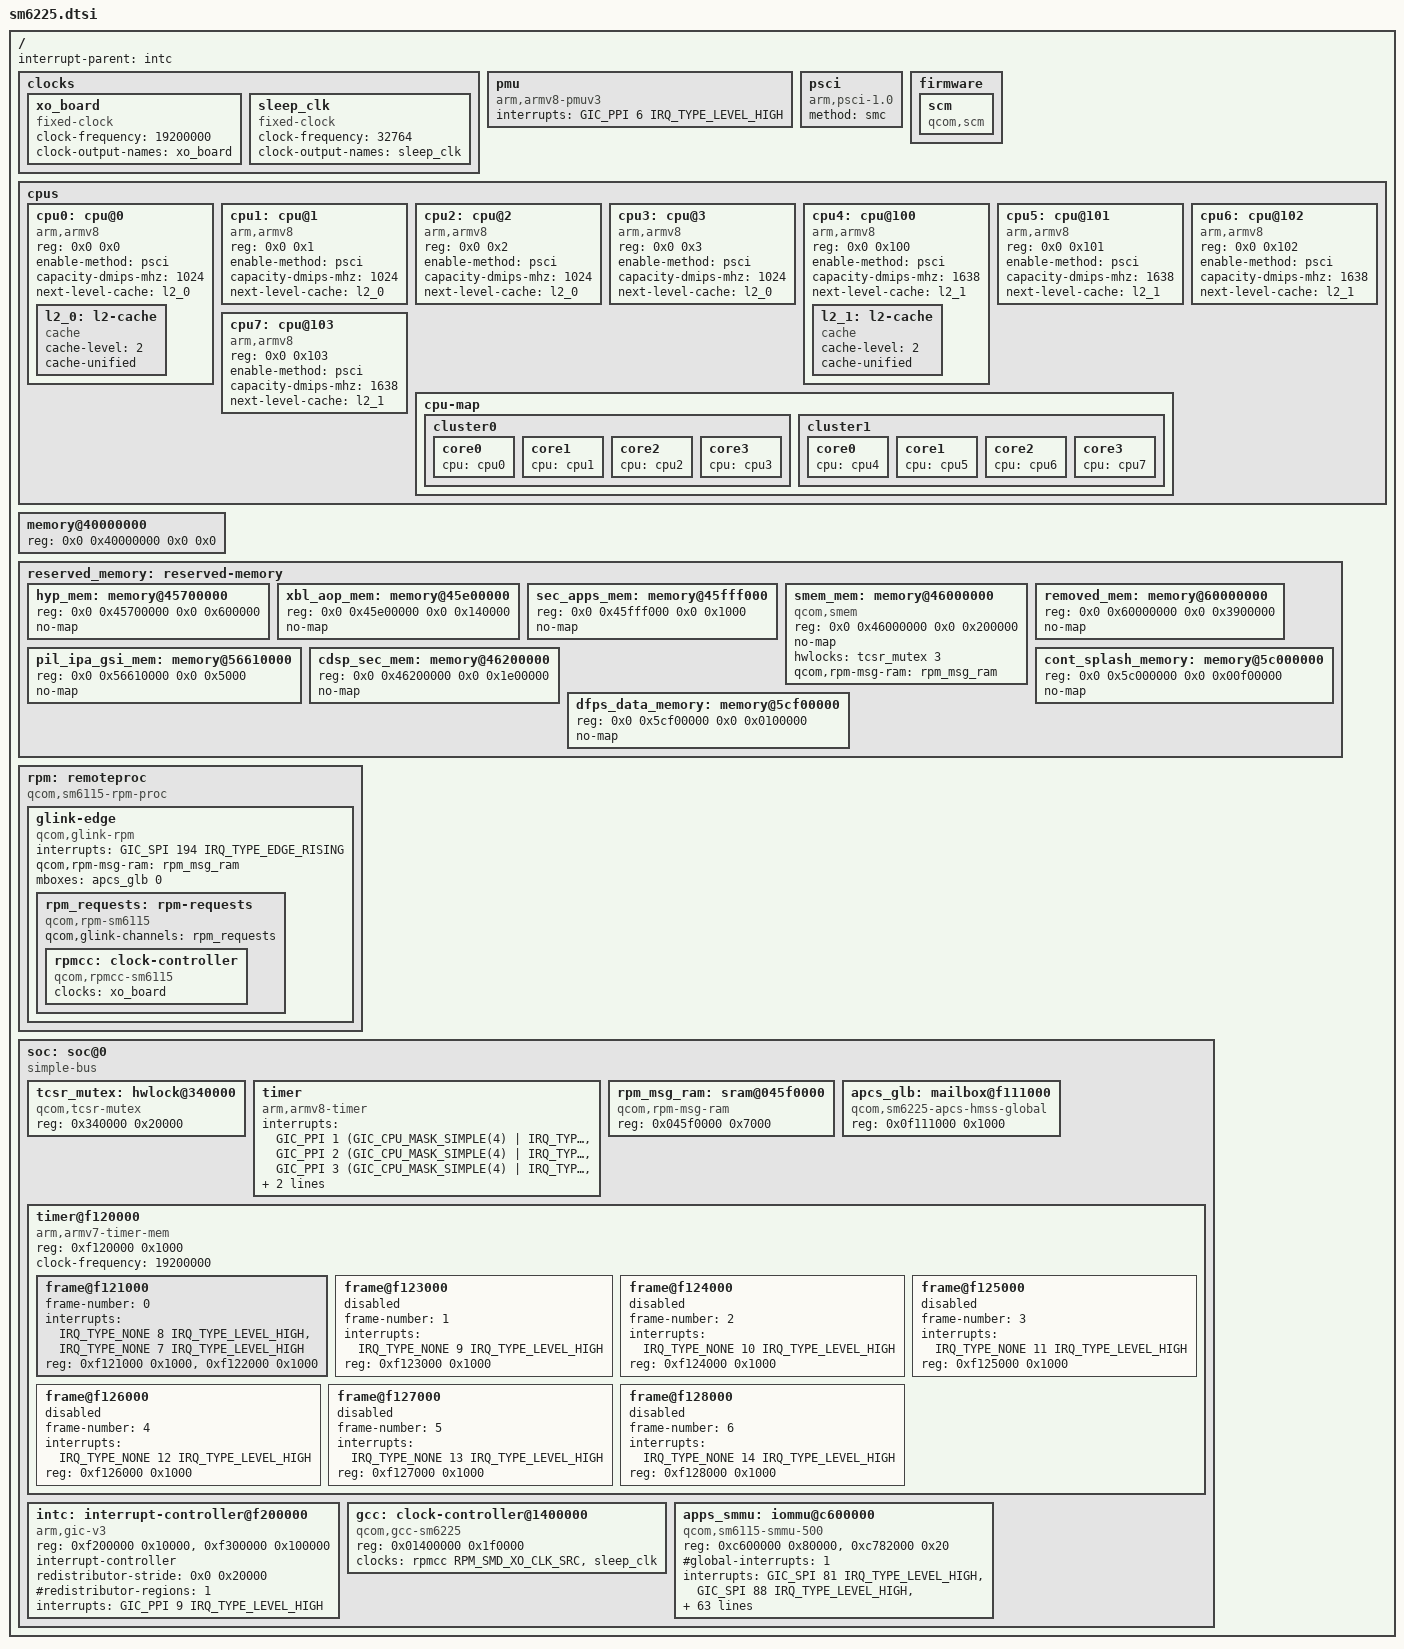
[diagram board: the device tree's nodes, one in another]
// SPDX-License-Identifier: BSD-3-Clause
/*
 * Copyright (c) 2026, Rayan Marzouk <rayanmarzouk743@gmail.com>
 */

#include <dt-bindings/interrupt-controller/arm-gic.h>
#include <dt-bindings/clock/qcom,rpmcc.h>
#include <dt-bindings/clock/qcom,gcc-sm6225.h>
#include <dt-bindings/firmware/qcom,scm.h>

/ {
	#address-cells = <2>;
	#size-cells = <2>;

	interrupt-parent = <&intc>;

	clocks {
		xo_board: xo_board {
			compatible = "fixed-clock";
			clock-frequency = <19200000>;
			clock-output-names = "xo_board";
			#clock-cells = <0>;
		};

		sleep_clk: sleep_clk {
			compatible = "fixed-clock";
			clock-frequency = <32764>;
			clock-output-names = "sleep_clk";
			#clock-cells = <0>;
		};
	};

	pmu {
		compatible = "arm,armv8-pmuv3";
		interrupts = <GIC_PPI 6 IRQ_TYPE_LEVEL_HIGH>;
	};

	psci {
		compatible = "arm,psci-1.0";
		method = "smc";
	};

	firmware {
        scm {
            compatible = "qcom,scm";
			#reset-cells = <1>;
        };
    };

	cpus {
		#address-cells = <2>;
		#size-cells = <0>;

		cpu0: cpu@0 {
			device_type = "cpu";
			compatible = "arm,armv8";
			reg = <0x0 0x0>;
			enable-method = "psci";
			capacity-dmips-mhz = <1024>;
			next-level-cache = <&l2_0>;
			l2_0: l2-cache {
				compatible = "cache";
				cache-level = <2>;
				cache-unified;
			};
		};

		cpu1: cpu@1 {
			device_type = "cpu";
			compatible = "arm,armv8";
			reg = <0x0 0x1>;
			enable-method = "psci";
			capacity-dmips-mhz = <1024>;
			next-level-cache = <&l2_0>;
		};

		cpu2: cpu@2 {
			device_type = "cpu";
			compatible = "arm,armv8";
			reg = <0x0 0x2>;
			enable-method = "psci";
			capacity-dmips-mhz = <1024>;
			next-level-cache = <&l2_0>;
		};

		cpu3: cpu@3 {
			device_type = "cpu";
			compatible = "arm,armv8";
			reg = <0x0 0x3>;
			enable-method = "psci";
			capacity-dmips-mhz = <1024>;
			next-level-cache = <&l2_0>;
		};

		cpu4: cpu@100 {
			device_type = "cpu";
			compatible = "arm,armv8";
			reg = <0x0 0x100>;
			enable-method = "psci";
			capacity-dmips-mhz = <1638>;
			next-level-cache = <&l2_1>;
			l2_1: l2-cache {
				compatible = "cache";
				cache-level = <2>;
				cache-unified;
			};
		};

		cpu5: cpu@101 {
			device_type = "cpu";
			compatible = "arm,armv8";
			reg = <0x0 0x101>;
			enable-method = "psci";
			capacity-dmips-mhz = <1638>;
			next-level-cache = <&l2_1>;
		};

		cpu6: cpu@102 {
			device_type = "cpu";
			compatible = "arm,armv8";
			reg = <0x0 0x102>;
			enable-method = "psci";
			capacity-dmips-mhz = <1638>;
			next-level-cache = <&l2_1>;
		};

		cpu7: cpu@103 {
			device_type = "cpu";
			compatible = "arm,armv8";
			reg = <0x0 0x103>;
			enable-method = "psci";
			capacity-dmips-mhz = <1638>;
			next-level-cache = <&l2_1>;
		};

		cpu-map {
			cluster0 {
				core0 {
					cpu = <&cpu0>;
				};

				core1 {
					cpu = <&cpu1>;
				};

				core2 {
					cpu = <&cpu2>;
				};

				core3 {
					cpu = <&cpu3>;
				};
			};

			cluster1 {
				core0 {
					cpu = <&cpu4>;
				};

				core1 {
					cpu = <&cpu5>;
				};

				core2 {
					cpu = <&cpu6>;
				};

				core3 {
					cpu = <&cpu7>;
				};
			};
		};
	};

	memory@40000000 {
		/* We expect the bootloader to fill in the size */
		reg = <0x0 0x40000000 0x0 0x0>;
		device_type = "memory";
	};

	reserved_memory: reserved-memory {
		#address-cells = <2>;
		#size-cells = <2>;
		ranges;

		hyp_mem: memory@45700000 {
			reg = <0x0 0x45700000 0x0 0x600000>;
			no-map;
		};

		xbl_aop_mem: memory@45e00000 {
			reg = <0x0 0x45e00000 0x0 0x140000>;
			no-map;
		};

		sec_apps_mem: memory@45fff000 {
			reg = <0x0 0x45fff000 0x0 0x1000>;
			no-map;
		};

		smem_mem: memory@46000000 {
			compatible = "qcom,smem";
			reg = <0x0 0x46000000 0x0 0x200000>;
			no-map;

			hwlocks = <&tcsr_mutex 3>;
			qcom,rpm-msg-ram = <&rpm_msg_ram>;
		};

		removed_mem: memory@60000000 {
			reg = <0x0 0x60000000 0x0 0x3900000>;
			no-map;
		};

		pil_ipa_gsi_mem: memory@56610000 {
			reg = <0x0 0x56610000 0x0 0x5000>;
			no-map;
		};

		cdsp_sec_mem: memory@46200000 {
			reg = <0x0 0x46200000 0x0 0x1e00000>;
			no-map;
		};

		cont_splash_memory: memory@5c000000 {
			reg = <0x0 0x5c000000 0x0 0x00f00000>;
			no-map;
		};

		dfps_data_memory: memory@5cf00000 {
			reg = <0x0 0x5cf00000 0x0 0x0100000>;
			no-map;
		};

	};

	rpm: remoteproc {
		compatible = "qcom,sm6115-rpm-proc", "qcom,rpm-proc";

		glink-edge {
			compatible = "qcom,glink-rpm";

			interrupts = <GIC_SPI 194 IRQ_TYPE_EDGE_RISING>;
			qcom,rpm-msg-ram = <&rpm_msg_ram>;
			mboxes = <&apcs_glb 0>;

			rpm_requests: rpm-requests {
				compatible = "qcom,rpm-sm6115", "qcom,glink-smd-rpm";
				qcom,glink-channels = "rpm_requests";

				rpmcc: clock-controller {
					compatible = "qcom,rpmcc-sm6115", "qcom,rpmcc";
					clocks = <&xo_board>;
					clock-names = "xo";
					#clock-cells = <1>;
				};
			};
		};
	};

	soc: soc@0 {
		compatible = "simple-bus";
		#address-cells = <1>;
		#size-cells = <1>;
		ranges = <0x0 0x0 0x0 0xffffffff>;

		tcsr_mutex: hwlock@340000 {
			compatible = "qcom,tcsr-mutex";
			reg = <0x340000 0x20000>;
			#hwlock-cells = <1>;
		};

		timer {
			compatible = "arm,armv8-timer";
			interrupts = <GIC_PPI 1 (GIC_CPU_MASK_SIMPLE(4) | IRQ_TYPE_LEVEL_LOW)>,
			     <GIC_PPI 2 (GIC_CPU_MASK_SIMPLE(4) | IRQ_TYPE_LEVEL_LOW)>,
			     <GIC_PPI 3 (GIC_CPU_MASK_SIMPLE(4) | IRQ_TYPE_LEVEL_LOW)>,
			     <GIC_PPI 0 (GIC_CPU_MASK_SIMPLE(4) | IRQ_TYPE_LEVEL_LOW)>;
			clock-frequency = <19200000>;
		};

		rpm_msg_ram: sram@045f0000 {
			compatible = "qcom,rpm-msg-ram";
			reg = <0x045f0000 0x7000>;
		};

		apcs_glb: mailbox@f111000 {
			compatible = "qcom,sm6225-apcs-hmss-global",
				     "qcom,msm8994-apcs-kpss-global";
			reg = <0x0f111000 0x1000>;

			#mbox-cells = <1>;
		};

		timer@f120000 {
			#address-cells = <1>;
			#size-cells = <1>;
			ranges;
			compatible = "arm,armv7-timer-mem";
			reg = <0xf120000 0x1000>;
			clock-frequency = <19200000>;

			frame@f121000 {
				frame-number = <0>;
				interrupts = <IRQ_TYPE_NONE 8 IRQ_TYPE_LEVEL_HIGH>,
						<IRQ_TYPE_NONE 7 IRQ_TYPE_LEVEL_HIGH>;
				reg = <0xf121000 0x1000>,
					<0xf122000 0x1000>;
			};

			frame@f123000 {
				frame-number = <1>;
				interrupts = <IRQ_TYPE_NONE 9 IRQ_TYPE_LEVEL_HIGH>;
				reg = <0xf123000 0x1000>;
				status = "disabled";
			};

			frame@f124000 {
				frame-number = <2>;
				interrupts = <IRQ_TYPE_NONE 10 IRQ_TYPE_LEVEL_HIGH>;
				reg = <0xf124000 0x1000>;
				status = "disabled";
			};

			frame@f125000 {
				frame-number = <3>;
				interrupts = <IRQ_TYPE_NONE 11 IRQ_TYPE_LEVEL_HIGH>;
				reg = <0xf125000 0x1000>;
				status = "disabled";
			};

			frame@f126000 {
				frame-number = <4>;
				interrupts = <IRQ_TYPE_NONE 12 IRQ_TYPE_LEVEL_HIGH>;
				reg = <0xf126000 0x1000>;
				status = "disabled";
			};

			frame@f127000 {
				frame-number = <5>;
				interrupts = <IRQ_TYPE_NONE 13 IRQ_TYPE_LEVEL_HIGH>;
				reg = <0xf127000 0x1000>;
				status = "disabled";
			};

			frame@f128000 {
				frame-number = <6>;
				interrupts = <IRQ_TYPE_NONE 14 IRQ_TYPE_LEVEL_HIGH>;
				reg = <0xf128000 0x1000>;
				status = "disabled";
			};
		};

		intc: interrupt-controller@f200000 {
			compatible = "arm,gic-v3";
			reg = <0xf200000 0x10000>,     /* GICD */
		      <0xf300000 0x100000>;    /* GICR * 8 */
			interrupt-controller;
			#interrupt-cells = <3>;
			redistributor-stride = <0x0 0x20000>;
			#redistributor-regions = <1>;
			interrupts = <GIC_PPI 9 IRQ_TYPE_LEVEL_HIGH>;
		};

		gcc: clock-controller@1400000 {
			compatible = "qcom,gcc-sm6225";
			reg = <0x01400000 0x1f0000>;
			clocks = <&rpmcc RPM_SMD_XO_CLK_SRC>, <&sleep_clk>;
			clock-names = "bi_tcxo", "sleep_clk";
			#clock-cells = <1>;
			#reset-cells = <1>;
			#power-domain-cells = <1>;
		};
		/* In donwstream, bengal/sm6115 smmu is used. */
		apps_smmu: iommu@c600000 {
			compatible = "qcom,sm6115-smmu-500", "qcom,smmu-500", "arm,mmu-500";
			reg = <0xc600000 0x80000>, <0xc782000 0x20>;
			#iommu-cells = <2>;
			#global-interrupts = <1>;

			interrupts = <GIC_SPI 81 IRQ_TYPE_LEVEL_HIGH>,
				     <GIC_SPI 88 IRQ_TYPE_LEVEL_HIGH>,
				     <GIC_SPI 89 IRQ_TYPE_LEVEL_HIGH>,
				     <GIC_SPI 90 IRQ_TYPE_LEVEL_HIGH>,
				     <GIC_SPI 91 IRQ_TYPE_LEVEL_HIGH>,
				     <GIC_SPI 92 IRQ_TYPE_LEVEL_HIGH>,
				     <GIC_SPI 93 IRQ_TYPE_LEVEL_HIGH>,
				     <GIC_SPI 94 IRQ_TYPE_LEVEL_HIGH>,
				     <GIC_SPI 95 IRQ_TYPE_LEVEL_HIGH>,
				     <GIC_SPI 96 IRQ_TYPE_LEVEL_HIGH>,
				     <GIC_SPI 97 IRQ_TYPE_LEVEL_HIGH>,
				     <GIC_SPI 98 IRQ_TYPE_LEVEL_HIGH>,
				     <GIC_SPI 99 IRQ_TYPE_LEVEL_HIGH>,
				     <GIC_SPI 100 IRQ_TYPE_LEVEL_HIGH>,
				     <GIC_SPI 101 IRQ_TYPE_LEVEL_HIGH>,
				     <GIC_SPI 102 IRQ_TYPE_LEVEL_HIGH>,
				     <GIC_SPI 103 IRQ_TYPE_LEVEL_HIGH>,
				     <GIC_SPI 104 IRQ_TYPE_LEVEL_HIGH>,
				     <GIC_SPI 105 IRQ_TYPE_LEVEL_HIGH>,
				     <GIC_SPI 106 IRQ_TYPE_LEVEL_HIGH>,
				     <GIC_SPI 107 IRQ_TYPE_LEVEL_HIGH>,
				     <GIC_SPI 108 IRQ_TYPE_LEVEL_HIGH>,
				     <GIC_SPI 109 IRQ_TYPE_LEVEL_HIGH>,
				     <GIC_SPI 110 IRQ_TYPE_LEVEL_HIGH>,
				     <GIC_SPI 111 IRQ_TYPE_LEVEL_HIGH>,
				     <GIC_SPI 112 IRQ_TYPE_LEVEL_HIGH>,
				     <GIC_SPI 113 IRQ_TYPE_LEVEL_HIGH>,
				     <GIC_SPI 114 IRQ_TYPE_LEVEL_HIGH>,
				     <GIC_SPI 115 IRQ_TYPE_LEVEL_HIGH>,
				     <GIC_SPI 116 IRQ_TYPE_LEVEL_HIGH>,
				     <GIC_SPI 117 IRQ_TYPE_LEVEL_HIGH>,
				     <GIC_SPI 118 IRQ_TYPE_LEVEL_HIGH>,
				     <GIC_SPI 119 IRQ_TYPE_LEVEL_HIGH>,
				     <GIC_SPI 120 IRQ_TYPE_LEVEL_HIGH>,
				     <GIC_SPI 121 IRQ_TYPE_LEVEL_HIGH>,
				     <GIC_SPI 122 IRQ_TYPE_LEVEL_HIGH>,
				     <GIC_SPI 123 IRQ_TYPE_LEVEL_HIGH>,
				     <GIC_SPI 124 IRQ_TYPE_LEVEL_HIGH>,
				     <GIC_SPI 125 IRQ_TYPE_LEVEL_HIGH>,
				     <GIC_SPI 126 IRQ_TYPE_LEVEL_HIGH>,
				     <GIC_SPI 127 IRQ_TYPE_LEVEL_HIGH>,
				     <GIC_SPI 128 IRQ_TYPE_LEVEL_HIGH>,
				     <GIC_SPI 129 IRQ_TYPE_LEVEL_HIGH>,
				     <GIC_SPI 130 IRQ_TYPE_LEVEL_HIGH>,
				     <GIC_SPI 131 IRQ_TYPE_LEVEL_HIGH>,
				     <GIC_SPI 132 IRQ_TYPE_LEVEL_HIGH>,
				     <GIC_SPI 133 IRQ_TYPE_LEVEL_HIGH>,
				     <GIC_SPI 134 IRQ_TYPE_LEVEL_HIGH>,
				     <GIC_SPI 135 IRQ_TYPE_LEVEL_HIGH>,
				     <GIC_SPI 136 IRQ_TYPE_LEVEL_HIGH>,
				     <GIC_SPI 137 IRQ_TYPE_LEVEL_HIGH>,
				     <GIC_SPI 138 IRQ_TYPE_LEVEL_HIGH>,
				     <GIC_SPI 139 IRQ_TYPE_LEVEL_HIGH>,
				     <GIC_SPI 140 IRQ_TYPE_LEVEL_HIGH>,
				     <GIC_SPI 141 IRQ_TYPE_LEVEL_HIGH>,
				     <GIC_SPI 142 IRQ_TYPE_LEVEL_HIGH>,
				     <GIC_SPI 143 IRQ_TYPE_LEVEL_HIGH>,
				     <GIC_SPI 144 IRQ_TYPE_LEVEL_HIGH>,
				     <GIC_SPI 145 IRQ_TYPE_LEVEL_HIGH>,
				     <GIC_SPI 146 IRQ_TYPE_LEVEL_HIGH>,
				     <GIC_SPI 147 IRQ_TYPE_LEVEL_HIGH>,
				     <GIC_SPI 148 IRQ_TYPE_LEVEL_HIGH>,
				     <GIC_SPI 149 IRQ_TYPE_LEVEL_HIGH>,
				     <GIC_SPI 150 IRQ_TYPE_LEVEL_HIGH>,
				     <GIC_SPI 151 IRQ_TYPE_LEVEL_HIGH>;
		};
	};
};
